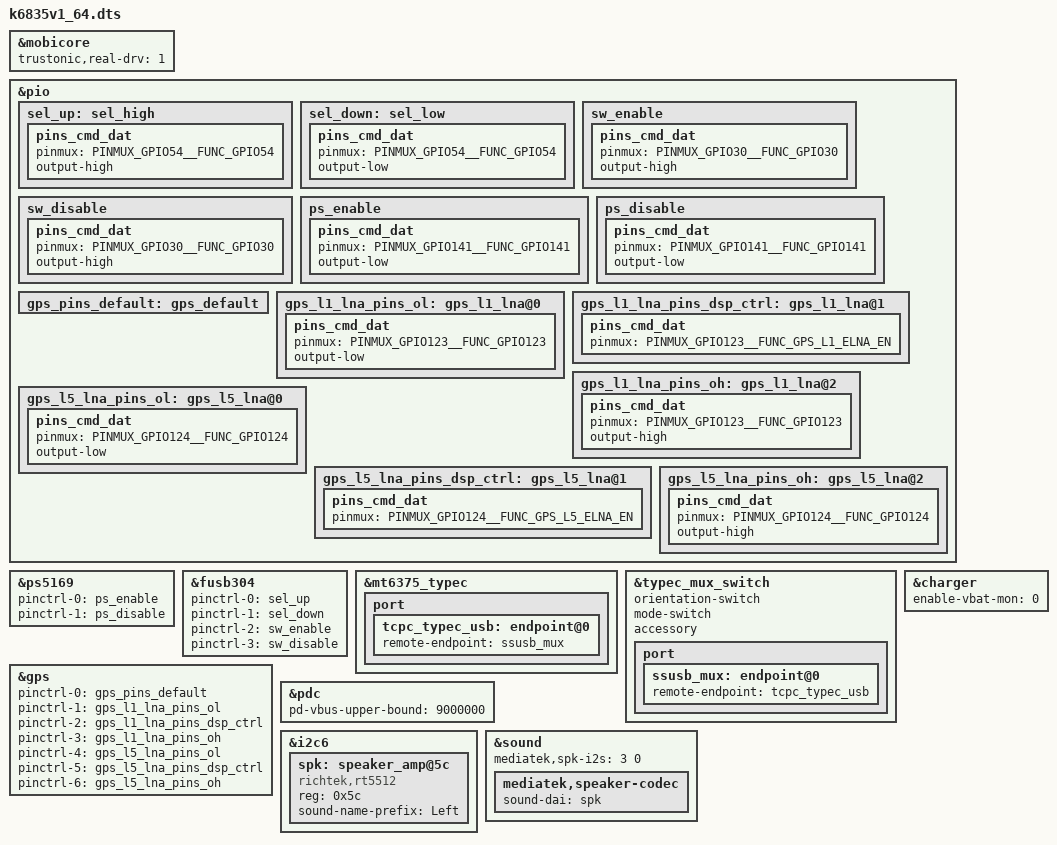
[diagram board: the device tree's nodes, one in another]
// SPDX-License-Identifier: (GPL-2.0 OR MIT)
/*
 * Copyright (C) 2022 MediaTek Inc.
 */
/dts-v1/;
/plugin/;
#include <dt-bindings/interrupt-controller/arm-gic.h>
#include <dt-bindings/interrupt-controller/irq.h>
#include <dt-bindings/phy/phy.h>
#include <dt-bindings/pinctrl/mt6835-pinfunc.h>
#include "mediatek/mt6835_6377.dtsi"
#include "mediatek/cust_mt6835_camera.dtsi"

/* Trustonic Mobilecore real driver */
&mobicore{
	trustonic,real-drv = <1>;
};



/* usb typec mux start */
&pio {
	sel_up: sel_high {
		pins_cmd_dat {
			pinmux = <PINMUX_GPIO54__FUNC_GPIO54>;
			output-high;
		};
	};

	sel_down: sel_low  {
		pins_cmd_dat {
			pinmux = <PINMUX_GPIO54__FUNC_GPIO54>;
			output-low;
		};
	};

	sw_enable: sw_enable {
		pins_cmd_dat {
			pinmux = <PINMUX_GPIO30__FUNC_GPIO30>;
			output-high;
		};
	};

	sw_disable: sw_disable {
		pins_cmd_dat {
			pinmux = <PINMUX_GPIO30__FUNC_GPIO30>;
			output-high;
		};
	};

	ps_enable: ps_enable {
		pins_cmd_dat {
			pinmux = <PINMUX_GPIO141__FUNC_GPIO141>;
			output-low;
		};
	};

	ps_disable: ps_disable {
		pins_cmd_dat {
			pinmux = <PINMUX_GPIO141__FUNC_GPIO141>;
			output-low;
		};
	};
};

&ps5169 {
	pinctrl-names = "enable", "disable";
	pinctrl-0 = <&ps_enable>;
	pinctrl-1 = <&ps_disable>;
	status = "okay";
};

&fusb304 {
	pinctrl-names = "sel_up", "sel_down",
		"enable", "disable";
	pinctrl-0 = <&sel_up>;
	pinctrl-1 = <&sel_down>;
	pinctrl-2 = <&sw_enable>;
	pinctrl-3 = <&sw_disable>;
	status = "okay";
};

&mt6375_typec {
	port {
		tcpc_typec_usb: endpoint@0 {
			remote-endpoint = <&ssusb_mux>;
		};
	};
};

&typec_mux_switch {
	orientation-switch;
	mode-switch;
	accessory;
	port {
		ssusb_mux: endpoint@0 {
			remote-endpoint = <&tcpc_typec_usb>;
		};
	};
};
/* usb typec mux end*/

/* GPS GPIO standardization start */
&pio {
	gps_pins_default: gps_default {
	};
	gps_l1_lna_pins_ol: gps_l1_lna@0 {
		pins_cmd_dat {
			pinmux = <PINMUX_GPIO123__FUNC_GPIO123>;
			output-low;
		};
	};
	gps_l1_lna_pins_dsp_ctrl: gps_l1_lna@1 {
		pins_cmd_dat {
			pinmux = <PINMUX_GPIO123__FUNC_GPS_L1_ELNA_EN>;
		};
	};
	gps_l1_lna_pins_oh: gps_l1_lna@2 {
		pins_cmd_dat {
			pinmux = <PINMUX_GPIO123__FUNC_GPIO123>;
			output-high;
		};
	};
	gps_l5_lna_pins_ol: gps_l5_lna@0 {
		pins_cmd_dat {
			pinmux = <PINMUX_GPIO124__FUNC_GPIO124>;
			output-low;
		};
	};
	gps_l5_lna_pins_dsp_ctrl: gps_l5_lna@1 {
		pins_cmd_dat {
			pinmux = <PINMUX_GPIO124__FUNC_GPS_L5_ELNA_EN>;
		};
	};
	gps_l5_lna_pins_oh: gps_l5_lna@2 {
		pins_cmd_dat {
			pinmux = <PINMUX_GPIO124__FUNC_GPIO124>;
			output-high;
		};
	};
};

&gps {
	pinctrl-names = "default",
		"gps_l1_lna_disable",
		"gps_l1_lna_dsp_ctrl",
		"gps_l1_lna_enable",
		"gps_l5_lna_disable",
		"gps_l5_lna_dsp_ctrl",
		"gps_l5_lna_enable";
	pinctrl-0 = <&gps_pins_default>;
	pinctrl-1 = <&gps_l1_lna_pins_ol>;
	pinctrl-2 = <&gps_l1_lna_pins_dsp_ctrl>;
	pinctrl-3 = <&gps_l1_lna_pins_oh>;
	pinctrl-4 = <&gps_l5_lna_pins_ol>;
	pinctrl-5 = <&gps_l5_lna_pins_dsp_ctrl>;
	pinctrl-6 = <&gps_l5_lna_pins_oh>;
	status = "okay";
};
/* GPS GPIO standardization end */

#include "mediatek/cust_mt6835_camera_6377_v4l2.dtsi"
#include "mediatek/cust_mt6835_touch_6377_1080x2400.dtsi"

&pdc {
	pd-vbus-upper-bound = <9000000>;
};

&charger{
	enable-vbat-mon = <0>;
};

&i2c6 {
	spk: speaker_amp@5c {
		compatible = "richtek,rt5512";
		#sound-dai-cells = <0>;
		reg = <0x5c>;
		status = "okay";
		sound-name-prefix = "Left";
	};
};

&sound {
	mediatek,spk-i2s = <3 0>;
	mediatek,speaker-codec {
		sound-dai = <&spk>;
	};
};

#include <k6835v1_64/cust.dtsi>
/*End of this file, DO NOT ADD ANYTHING HERE*/
